# I94100_v1_3 register map
File version: 1.0
Registers are 32-bit, read-write, reset 0x0 unless marked. A register's access mark holds for its fields unless they carry their own. Offsets are from the block's base; [hi:lo] are bit positions; {n}, {i} and the like mark numbered series.

## SYS — SYS Register Map
Base 0x40000000
0x00 SYS_PDID ro reset 0x1D000500 (reset mask 0xFF00FF00) — Part Device Identification Number Register
  [31:0] PDID — Part Device Identification Number (Read Only). This register reflects device part number code. Software can read this register to identify which device is used.
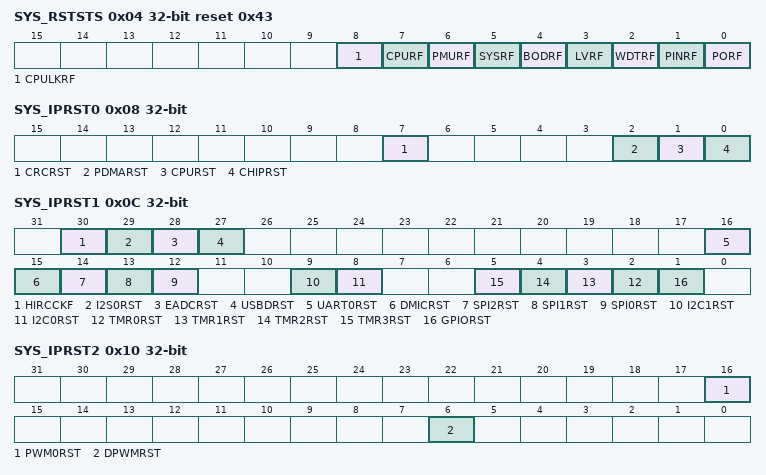
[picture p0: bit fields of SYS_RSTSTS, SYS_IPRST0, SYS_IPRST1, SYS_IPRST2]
0x04 SYS_RSTSTS reset 0x43 — System Reset Status Register
  [8] CPULKRF — CPU Lockup Reset Flag. Note: Write 1 to clear this bit to 0. Note: when ICE is connected, CPU lockup event sets this flag to 1 but will not reset chip.
    0=No reset from CPU lockup occurred; 1=The Cortex-M4 lockup occurred and chip is reset
  [7] CPURF — CPU Reset Flag. The CPU reset flag is set by hardware if software writes CPURST (SYS_IPRST0[1]) 1 to reset Cortex®-M4 Core and Flash Memory Controller (FMC). Note: Write 1 to clear this bit to 0.
    0=No reset from CPU; 1=The Cortex®-M4 Core and FMC are reset by software setting CPURST to 1
  [6] PMURF — PMU Reset Flag. Note: Write 1 to clear this bit to 0.
    0=No reset from POR, PINR, WDTR, LVR, BODR, SYSR and CPULKR; 1=When POR, PINR, WDTR, LVR, BODR, SYSR and CPULKR occurred
  [5] SYSRF — System Reset Flag. The system reset flag is set by the "Reset Signal" from the Cortex®-M4 Core to indicate the previous reset source. Note: Write 1 to clear this bit to 0.
    0=No reset from Cortex®-M4; 1=The Cortex®-M4 had issued the reset signal to reset the system by writing 1 to the bit SYSRESETREQ(AIRCR[2], Application Interrupt and Reset Control Register, address = 0xE000ED0C) in system control registers of Cortex®-M4 core
  [4] BODRF — BOD Reset Flag. The BOD reset flag is set by the "Reset Signal" from the Brown-Out Detector to indicate the previous reset source. Note: Write 1 to clear this bit to 0.
    0=No reset from BOD; 1=The BOD had issued the reset signal to reset the system
  [3] LVRF — LVR Reset Flag. The LVR reset flag is set by the "Reset Signal" from the Low Voltage Reset Controller to indicate the previous reset source. Note: Write 1 to clear this bit to 0.
    0=No reset from LVR; 1=LVR controller issued the reset signal to reset the system
  [2] WDTRF — WDT Reset Flag. The WDT reset flag is set by the "Reset Signal" from the Watchdog Timer or Window Watchdog Timer to indicate the previous reset source. Note1: Write 1 to clear this bit to 0. Note2: Watchdog Timer register RSTF(WDT_CTL[2]) bit is set if the system has been reset by WDT time-out reset. Window Watchdog Timer register WWDTRF(WWDT_STATUS[1]) bit is set if the system has been reset by WWDT time-out reset.
    0=No reset from watchdog timer or window watchdog timer; 1=The watchdog timer or window watchdog timer issued the reset signal to reset the system
  [1] PINRF — NRESET Pin Reset Flag. The nRESET pin reset flag is set by the "Reset Signal" from the nRESET Pin to indicate the previous reset source. Note: Write 1 to clear this bit to 0.
    0=No reset from nRESET pin; 1=Pin nRESET issued the reset signal to reset the system
  [0] PORF — POR Reset Flag. The POR reset flag is set by the "Reset Signal" from the Power-on Reset (POR) Controller or bit CHIPRST (SYS_IPRST0[0]) to indicate the previous reset source. Note: Write 1 to clear this bit to 0.
    0=No reset from POR or CHIPRST; 1=Power-on Reset (POR) or CHIPRST issued the reset signal to reset the system
0x08 SYS_IPRST0 — Peripheral Reset Control Register 0
  [7] CRCRST — CRC Calculation Controller Reset (Write Protected). Set this bit to 1 will generate a reset signal to the CRC calculation controller. User needs to set this bit to 0 to release from the reset state. Note: This bit is write protected. Refer to the SYS_REGLCTL register.
    0=CRC calculation controller normal operation; 1=CRC calculation controller reset
  [2] PDMARST — PDMA Controller Reset (Write Protected). Setting this bit to 1 will generate a reset signal to the PDMA. User needs to set this bit to 0 to release from reset state. Note: This bit is write protected. Refer to the SYS_REGLCTL register.
    0=PDMA controller normal operation; 1=PDMA controller reset
  [1] CPURST — Processor Core One-shot Reset (Write Protected). Setting this bit will only reset the processor core and Flash Memory Controller(FMC); this bit will automatically return to 0 after the 2 clock cycles. Note: This bit is write protected. Refer to the SYS_REGLCTL register.
    0=Processor core normal operation; 1=Processor core one-shot reset
  [0] CHIPRST — Chip One-shot Reset (Write Protected). Setting this bit will reset the whole chip, including Processor core and all peripherals; this bit will automatically return to 0 after the 2 clock cycles. The CHIPRST is same as the POR reset, all the chip controllers are reset and the chip settings from flash configuration are also reloaded. About the difference between CHIPRST and SYSRESETREQ(AIRCR[2]), please refer to section 6.2.2. Note: This bit is write protected. Refer to the SYS_REGLCTL register.
    0=Chip normal operation; 1=Chip one-shot reset
0x0C SYS_IPRST1 — Peripheral Reset Control Register 1
  [30] HIRCCKF — HIRC Clock Filter Enable Bit
    0=HIRC clock filter Enabled; 1=HIRC clock filter Disabled
  [29] I2S0RST — I2S0 Controller Reset
    0=I2S0 controller normal operation; 1=I2S0 controller reset
  [28] EADCRST — EADC Controller Reset
    0=EADC controller normal operation; 1=EADC controller reset
  [27] USBDRST — USBD Controller Reset
    0=USBD controller normal operation; 1=USBD controller reset
  [16] UART0RST — UART0 Controller Reset
    0=UART0 controller normal operation; 1=UART0 controller reset
  [15] DMICRST — DMIC Controller Reset
    0=DMIC controller normal operation; 1=DMIC controller reset
  [14] SPI2RST — SPI2 Controller Reset
    0=SPI2 controller normal operation; 1=SPI2 controller reset
  [13] SPI1RST — SPI1 Controller Reset
    0=SPI1 controller normal operation; 1=SPI1 controller reset
  [12] SPI0RST — SPI0 Controller Reset
    0=SPI0 controller normal operation; 1=SPI0 controller reset
  [9] I2C1RST — I2C1 Controller Reset
    0=I2C1 controller normal operation; 1=I2C1 controller reset
  [8] I2C0RST — I2C0 Controller Reset
    0=I2C0 controller normal operation; 1=I2C0 controller reset
  [n+2] TMR{n}RST (n=0..3) — Timer{n} Controller Reset
    0=Timer{n} controller normal operation; 1=Timer{n} controller reset
  [1] GPIORST — GPIO Controller Reset
    0=GPIO controller normal operation; 1=GPIO controller reset
0x10 SYS_IPRST2 — Peripheral Reset Control Register 2
  [16] PWM0RST — PWM0 Controller Reset
    0=PWM0 controller normal operation; 1=PWM0 controller reset
  [6] DPWMRST — DPWM Controller Reset
    0=Audio DPWM controller normal operation; 1=Audio DPWM controller reset
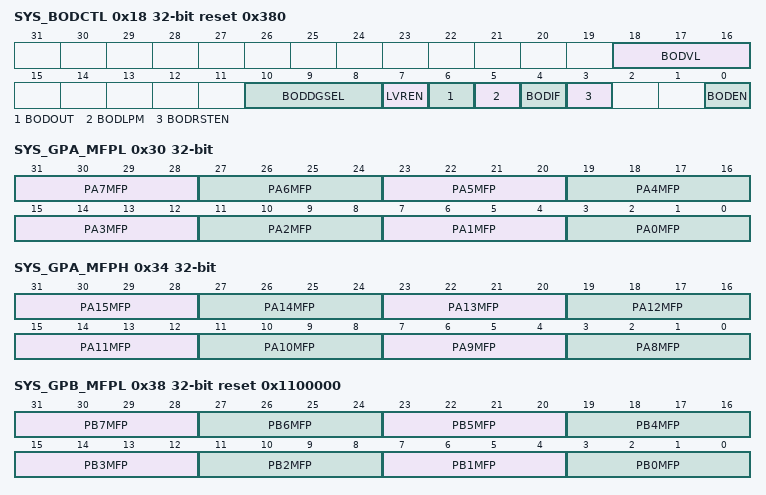
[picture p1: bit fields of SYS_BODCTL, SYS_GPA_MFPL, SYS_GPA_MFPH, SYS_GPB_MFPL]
0x18 SYS_BODCTL reset 0x380 (reset mask 0xFFF0FFF0) — Brown-out Detector Control Register
  [18:16] BODVL — Brown-out Detector Threshold Voltage Selection (Write Protected). The default value is set by flash controller user configuration register CBOV (CONFIG0 [23:21]). Note: These bits are write protected. Refer to the SYS_REGLCTL register.
    0=Brown-Out Detector threshold voltage is 1.6V; 1=Brown-Out Detector threshold voltage is 1.8V; 2=Brown-Out Detector threshold voltage is 2.0V; 3=Brown-Out Detector threshold voltage is 2.2V; 4=Brown-Out Detector threshold voltage is 2.4V; 5=Brown-Out Detector threshold voltage is 2.6V; 6=Brown-Out Detector threshold voltage is 2.8V; 7=Brown-Out Detector threshold voltage is 3.0V
  [10:8] BODDGSEL — Brown-out Detector Output De-glitch Time Select (Write Protected). Note: These bits are write protected. Refer to the SYS_REGLCTL register.
    0=Without de-glitch function; 1=3 system clock (HCLK); 2=7 system clock (HCLK); 3=15 system clock (HCLK); 4=31 system clock (HCLK); 5=63 system clock (HCLK); 6=127 system clock (HCLK); 7=255 system clock (HCLK)
  [7] LVREN — Low Voltage Reset Enable Bit (Write Protected). The LVR function resets the chip when the input power voltage is lower than LVR circuit setting. LVR function is enabled by default. Note: This bit is write protected. Refer to the SYS_REGLCTL register.
    0=Low Voltage Reset function Disabled; 1=Low Voltage Reset function Enabled
  [6] BODOUT — Brown-out Detector Output Status. The detected voltage is lower than BODVL setting. If the BODEN is 0, BOD function is disabled and this bit will be 0.
    0=Brown-out Detector output status is 0; 1=Brown-out Detector output status is 1
  [5] BODLPM — Brown-out Detector Low Power Mode (Write Protected). Note 1: The low power mode can reduce the current to about 1/10 but slow the BOD response. Note 2: This bit is write protected. Refer to the SYS_REGLCTL register.
    0=BOD operate in normal mode (default); 1=BOD Low Power mode Enabled
  [4] BODIF — Brown-out Detector Interrupt Flag. Note: Write 1 to clear this bit to 0.
    0=Brown-out Detector has not detected a BOD event on VDD down through or up through the voltage of BODVL setting; 1=When Brown-out Detector detects that VDD crosses BODLVL setting from either direction, this bit is set to 1 and the brown-out interrupt is requested if brown-out interrupt is enabled
  [3] BODRSTEN — Brown-out Reset Enable Bit (Write Protected). The default value is set by flash controller user configuration register CBORST(CONFIG0[20]) bit . Note 1: While the Brown-out Detector function is enabled (BODEN high) and BOD reset function is enabled (BODRSTEN high), BOD will assert a signal to reset chip when the detected voltage is lower than the threshold (BODOUT high). While the BOD function is enabled (BODEN high) and BOD interrupt function is enabled (BODRSTEN low), BOD will assert an interrupt if BODOUT is high. BOD interrupt will latch until BODEN is set to 0. BOD interrupt can be blocked by disabling the NVIC BOD interrupt or disabling BOD function (set BODEN low). Note 2: The reset value of SYS_BODCTL[3] is determined by user flash configuration. Note 3: This bit is write protected. Refer to the SYS_REGLCTL register.
    0=Brown-out "INTERRUPT" function Enabled; 1=Brown-out "RESET" function Enabled
  [0] BODEN — Brown-out Detector Enable Bit (Write Protected). The default value is set by flash controller user configuration register CBODEN (CONFIG0 [19]). Note 1: The reset value of SYS_BODCTL[0] is determined by user flash configuration. Note 2: Brown-out detector can only work when both BODEN(SYS_BODCTL[0]) and LVREN(SYS_BODCTL[7]) are set to 1. Note 3: When both BODEN(SYS_BODCTL[0]) and LVREN(SYS_BODCTL[7]) are set to 1, NVIC BOD interrupt must be enabled before entering power down mode. Note 4: This bit is write protected. Refer to the SYS_REGLCTL register.
    0=Brown-out Detector function Disabled; 1=Brown-out Detector function Enabled
0x24 SYS_PORCTL — Power-On-reset Controller Register
  [15:0] POROFF — Power-on Reset Enable Bit (Write Protected). When power is applied to device, the POR circuit generates a reset signal to reset the entire chip function. Noise on the power may cause the POR to become active again. User can disable internal POR circuit to avoid unpredictable noise to cause chip reset by writing 0x5AA5 to this field. The POR function will be active again when this field is set to another value or chip is reset by other reset source, including: nRESET, Watchdog, LVR reset, BOD reset, ICE reset command and the software-chip reset function. Note: This bit is write protected. Refer to the SYS_REGLCTL register.
0x2C SYS_USBPHY — USB PHY Control Register
  [8] USB_PHY_EN — USB PHY Enable (Write Protect). This bit is used to enable/disable USB PHY function.
    0=USB PHY function Disabled (default); 1=USB PHY function Enabled
0x30 SYS_GPA_MFPL — GPIOA Low Byte Multiple Function Control Register
  [31:28] PA7MFP — PA.7 Multi-function Pin Selection
  [27:24] PA6MFP — PA.6 Multi-function Pin Selection
  [23:20] PA5MFP — PA.5 Multi-function Pin Selection
  [19:16] PA4MFP — PA.4 Multi-function Pin Selection
  [15:12] PA3MFP — PA.3 Multi-function Pin Selection
  [11:8] PA2MFP — PA.2 Multi-function Pin Selection
  [7:4] PA1MFP — PA.1 Multi-function Pin Selection
  [3:0] PA0MFP — PA.0 Multi-function Pin Selection
0x34 SYS_GPA_MFPH — GPIOA High Byte Multiple Function Control Register
  [31:28] PA15MFP — PA.15 Multi-function Pin Selection
  [27:24] PA14MFP — PA.14 Multi-function Pin Selection
  [23:20] PA13MFP — PA.13 Multi-function Pin Selection
  [19:16] PA12MFP — PA.12 Multi-function Pin Selection
  [15:12] PA11MFP — PA.11 Multi-function Pin Selection
  [11:8] PA10MFP — PA.10 Multi-function Pin Selection
  [7:4] PA9MFP — PA.9 Multi-function Pin Selection
  [3:0] PA8MFP — PA.8 Multi-function Pin Selection
0x38 SYS_GPB_MFPL reset 0x1100000 — GPIOB Low Byte Multiple Function Control Register
  [31:28] PB7MFP — PB.7 Multi-function Pin Selection
  [27:24] PB6MFP — PB.6 Multi-function Pin Selection
  [23:20] PB5MFP — PB.5 Multi-function Pin Selection
  [19:16] PB4MFP — PB.4 Multi-function Pin Selection
  [15:12] PB3MFP — PB.3 Multi-function Pin Selection
  [11:8] PB2MFP — PB.2 Multi-function Pin Selection
  [7:4] PB1MFP — PB.1 Multi-function Pin Selection
  [3:0] PB0MFP — PB.0 Multi-function Pin Selection
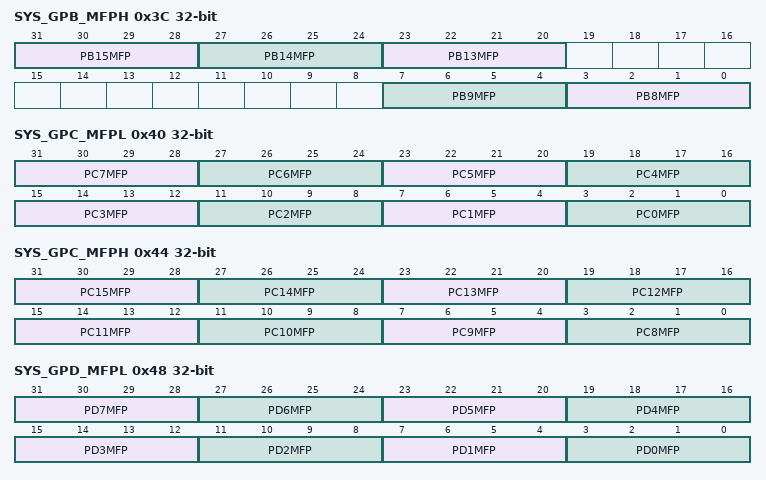
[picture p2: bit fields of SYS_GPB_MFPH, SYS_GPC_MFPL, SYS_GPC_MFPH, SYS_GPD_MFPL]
0x3C SYS_GPB_MFPH — GPIOB High Byte Multiple Function Control Register
  [31:28] PB15MFP — PB.15 Multi-function Pin Selection
  [27:24] PB14MFP — PB.14 Multi-function Pin Selection
  [23:20] PB13MFP — PB.13 Multi-function Pin Selection
  [7:4] PB9MFP — PB.9 Multi-function Pin Selection
  [3:0] PB8MFP — PB.8 Multi-function Pin Selection
0x40 SYS_GPC_MFPL — GPIOC Low Byte Multiple Function Control Register
  [31:28] PC7MFP — PC.7 Multi-function Pin Selection
  [27:24] PC6MFP — PC.6 Multi-function Pin Selection
  [23:20] PC5MFP — PC.5 Multi-function Pin Selection
  [19:16] PC4MFP — PC.4 Multi-function Pin Selection
  [15:12] PC3MFP — PC.3 Multi-function Pin Selection
  [11:8] PC2MFP — PC.2 Multi-function Pin Selection
  [7:4] PC1MFP — PC.1 Multi-function Pin Selection
  [3:0] PC0MFP — PC.0 Multi-function Pin Selection
0x44 SYS_GPC_MFPH — GPIOC High Byte Multiple Function Control Register
  [31:28] PC15MFP — PC.15 Multi-function Pin Selection
  [27:24] PC14MFP — PC.14 Multi-function Pin Selection
  [23:20] PC13MFP — PC.13 Multi-function Pin Selection
  [19:16] PC12MFP — PC.12 Multi-function Pin Selection
  [15:12] PC11MFP — PC.11 Multi-function Pin Selection
  [11:8] PC10MFP — PC.10 Multi-function Pin Selection
  [7:4] PC9MFP — PC.9 Multi-function Pin Selection
  [3:0] PC8MFP — PC.8 Multi-function Pin Selection
0x48 SYS_GPD_MFPL — GPIOD Low Byte Multiple Function Control Register
  [31:28] PD7MFP — PD.7 Multi-function Pin Selection
  [27:24] PD6MFP — PD.6 Multi-function Pin Selection
  [23:20] PD5MFP — PD.5 Multi-function Pin Selection
  [19:16] PD4MFP — PD.4 Multi-function Pin Selection
  [15:12] PD3MFP — PD.3 Multi-function Pin Selection
  [11:8] PD2MFP — PD.2 Multi-function Pin Selection
  [7:4] PD1MFP — PD.1 Multi-function Pin Selection
  [3:0] PD0MFP — PD.0 Multi-function Pin Selection
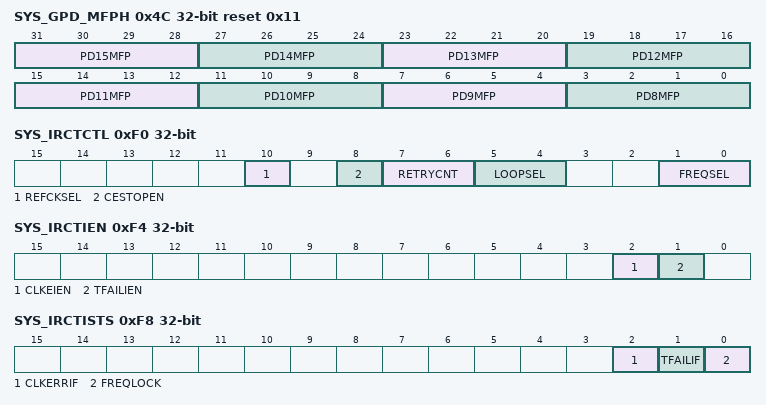
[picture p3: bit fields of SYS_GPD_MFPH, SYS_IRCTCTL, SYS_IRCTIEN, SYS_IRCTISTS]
0x4C SYS_GPD_MFPH reset 0x11 — GPIOD High Byte Multiple Function Control Register
  [31:28] PD15MFP — PD.15 Multi-function Pin Selection
  [27:24] PD14MFP — PD.14 Multi-function Pin Selection
  [23:20] PD13MFP — PD.13 Multi-function Pin Selection
  [19:16] PD12MFP — PD.12 Multi-function Pin Selection
  [15:12] PD11MFP — PD.11 Multi-function Pin Selection
  [11:8] PD10MFP — PD.10 Multi-function Pin Selection
  [7:4] PD9MFP — PD.9 Multi-function Pin Selection
  [3:0] PD8MFP — PD.8 Multi-function Pin Selection
0xC0 SYS_SRAM_INTCTL — System SRAM Interrupt Enable Control Register
  [0] PERRIEN — SRAM Parity Check Error Interrupt Enable Bit
    0=SRAM parity check error interrupt Disabled; 1=SRAM parity check error interrupt Enabled
0xC4 SYS_SRAM_STATUS — System SRAM Parity Error Status Register
  [0] PERRIF — SRAM Parity Check Error Flag. This bit indicates the System SRAM parity error occurred. Write 1 to clear this bit to 0.
    0=No System SRAM parity error; 1=System SRAM parity error occur
0xC8 SYS_SRAM_ERRADDR ro — System SRAM Parity Check Error Address Register
  [31:0] ERRADDR — System SRAM Parity Error Address. This register shows system SRAM parity error byte address.
0xF0 SYS_IRCTCTL — HIRC Trim Control Register
  [10] REFCKSEL — Reference Clock Selection
    0=HIRC trim reference clock is from LXT (32.768 kHz); 1=HIRC trim reference clock is from USB SOF (Start-Of-Frame) packet
  [8] CESTOPEN — Clock Error Stop Enable Bit
    0=The trim operation is keep going if clock is inaccuracy; 1=The trim operation is stopped if clock is inaccuracy
  [7:6] RETRYCNT — Trim Value Update Limitation Count. This field defines that how many times the auto trim circuit will try to update the HIRC trim value before the frequency of HIRC locked. Once the HIRC locked, the internal trim value update counter will be reset. If the trim value update counter reached this limitation value and frequency of HIRC still doesn't lock, the auto trim operation will be disabled and FREQSEL will be cleared to 00.
    0=Trim retry count limitation is 64 loops; 1=Trim retry count limitation is 128 loops; 2=Trim retry count limitation is 256 loops; 3=Trim retry count limitation is 512 loops
  [5:4] LOOPSEL — Trim Calculation Loop Selection. This field defines that trim value calculation is based on how many reference clocks. Note: For example, if LOOPSEL is set as 00, auto trim circuit will calculate trim value based on the average frequency difference in 4 clocks of reference clock.
    0=Trim value calculation is based on average difference in 4 clocks of reference clock; 1=Trim value calculation is based on average difference in 8 clocks of reference clock; 2=Trim value calculation is based on average difference in 16 clocks of reference clock; 3=Trim value calculation is based on average difference in 32 clocks of reference clock
  [1:0] FREQSEL — Trim Frequency Selection. This field indicates the target frequency of 48 MHz and 49.152 MHz internal high speed RC oscillator (HIRC) auto trim. During auto trim operation, if clock error detected with CESTOPEN is set to 1 or trim retry limitation count reached, this field will be cleared to 00 automatically.
    1=Enable HIRC auto trim function and trim HIRC to 48 MHz; 3=Enable HIRC auto trim function and trim HIRC to 49.152 MHz
0xF4 SYS_IRCTIEN — HIRC Trim Interrupt Enable Register
  [2] CLKEIEN — Clock Error Interrupt Enable Bit. This bit controls if CPU would get an interrupt while clock is inaccuracy during auto trim operation. If this bit is set to1, and CLKERRIF(SYS_IRCTISTS[2]) is set during auto trim operation, an interrupt will be triggered to notify the clock frequency is inaccuracy.
    0=Disable CLKERRIF(SYS_IRCTISTS[2]) status to trigger an interrupt to CPU; 1=Enable CLKERRIF(SYS_IRCTISTS[2]) status to trigger an interrupt to CPU
  [1] TFAILIEN — Trim Failure Interrupt Enable Bit. This bit controls if an interrupt will be triggered while HIRC trim value update limitation count reached and HIRC frequency still not locked on target frequency set by FREQSEL(SYS_IRCTCTL[1:0]). If this bit is high and TFAILIF(SYS_IRCTISTS[1]) is set during auto trim operation, an interrupt will be triggered to notify that HIRC trim value update limitation count was reached.
    0=Disable TFAILIF(SYS_IRCTISTS[1]) status to trigger an interrupt to CPU; 1=Enable TFAILIF(SYS_IRCTISTS[1]) status to trigger an interrupt to CPU
0xF8 SYS_IRCTISTS — HIRC Trim Interrupt Status Register
  [2] CLKERRIF — Clock Error Interrupt Status. When the frequency of 32.768 kHz external low speed crystal oscillator (LXT) or internal high speed RC oscillator (HIRC) is shift larger to unreasonable value, this bit will be set and to be an indicate that clock frequency is inaccuracy. Once this bit is set to 1, the auto trim operation stopped and FREQSEL(SYS_IRCTCL[1:0]) will be cleared to 00 by hardware automatically if CESTOPEN(SYS_IRCTCTL[8]) is set to 1. If this bit is set and CLKEIEN(SYS_IRCTIEN[2]) is high, an interrupt will be triggered to notify the clock frequency is inaccuracy. Write 1 to clear this to 0.
    0=Clock frequency is accuracy; 1=Clock frequency is inaccuracy
  [1] TFAILIF — Trim Failure Interrupt Status. This bit indicates that HIRC trim value update limitation count reached and the HIRC clock frequency still doesn't be locked. Once this bit is set, the auto trim operation stopped and FREQSEL(SYS_IRCTCTL[1:0]) will be cleared to 00 by hardware automatically. If this bit is set and TFAILIEN(SYS_IRCTIEN[1]) is high, an interrupt will be triggered to notify that HIRC trim value update limitation count was reached. Write 1 to clear this to 0.
    0=Trim value update limitation count does not reach; 1=Trim value update limitation count reached and HIRC frequency still not locked
  [0] FREQLOCK — HIRC Frequency Lock Status. This bit indicates the HIRC frequency is locked. This is a status bit and doesn't trigger any interrupt. Write 1 to clear this to 0. This bit will be set automatically, if the frequecy is lock.
    0=The internal high-speed oscillator frequency doesn't lock at 48 MHz or 49.152 MHz yet; 1=The internal high-speed oscillator frequency locked at 48 MHz or 49.152 MHz
0x100 SYS_REGLCTL — Register Lock Control Register
  [7:0] REGLCTL wo — Register Lock Control Code (Write Only). Some registers have a write-protection function. To write to these registers, this write protection must be by writing the sequence value "59h", "16h", "88h" to this address. After this sequence is completed, the REGLCTL bit will be set to 1 and write-protected registers can be write accessed. Register Lock Control Disable Index (Read Only). The Protected registers are: SYS_IPRST0: address 0x4000_0008. SYS_BODCTL: address 0x4000_0018. SYS_PORCTL: address 0x4000_0024. SYS_USBPHY: address 0x4000_002C. CLK_PWRCTL: address 0x4000_0200 (bit[6] is not protected for power-down wake-up interrupt clear). SYS_RCADJ: address 0x4000_0110. CLK_APBCLK0 [0]: address 0x4000_0208 (bit[0] is watchdog clock enable). CLK_CLKSEL0: address 0x4000_0210 (for HCLK and CPU STCLK clock source select). CLK_CLKSEL1 [1:0]: address 0x4000_0214 (for watchdog clock source select). CLK_CLKSEL1 [31:30]: address 0x4000_0214 (for window watchdog clock source select). CLK_CLKDSTS: address 0x4000_0274. NMIEN: address 0x4000_0300. FMC_ISPCTL: address 0x4000_C000 (Flash ISP Control register). FMC_ISPTRG: address 0x4000_C010 (ISP Trigger Control register). FMC_ISPSTS: address 0x4000_C040. WDT_CTL: address 0x4004_0000. AHBMCTL: address 0x4000_0400. CLK_PLLCTL: address 0x4000_0240. PWM_CTL0: address 0x4005_8000. PWM_DTCTL0_1: address 0x4005_8070. PWM_DTCTL2_3: address 0x4005_8074. PWM_DTCTL4_5: address 0x4005_8078. PWM_BRKCTL0_1: address 0x4005_80C8. PWM_BRKCTL2_3: address 0x4005_80CC. PWM_BRKCTL4_5: address 0x4005_80D0. PWM_INTEN1: address 0x4005_80E4. PWM_INTSTS1: address 0x4005_80EC
    0=Write-protection Enabled for write protected registers. Any write to the protected registers is ignored; 1=Write-protection Disabled for write protected registers
0x110 SYS_RCADJ (reset mask 0xFFFFF000) — HIRC Trim Value Register
  [9:0] RCADJ — HIRC Trim Value (Write Protect). This bit is the protected bit, which means programming it needs to write "59h", "16h", "88h" to address 0x4000_0100 to disable register protection. Refer to the register SYS_REGLCTL at address SYS_BA+0x100. This field reflects the HIRC trim value. Software can update HIRC trim value by writing this field. Note: This bit is write protected. Refer to the SYS_REGLCTL register.
